# APM32F105xx register map
File version: 1.0
CPU: CM3 r2p1, little endian, no MPU, no FPU, 4 interrupt priority bits
Registers are 32-bit, read-write, reset 0x0 unless marked. A register's access mark holds for its fields unless they carry their own. Offsets are from the block's base; [hi:lo] are bit positions; {n}, {i} and the like mark numbered series.

## TMR6 — Advanced timer
Base 0x40001000
Same registers: TMR7 0x40001400
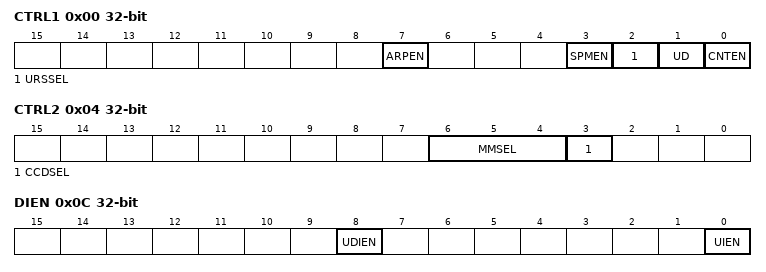
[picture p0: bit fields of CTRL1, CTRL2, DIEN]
0x00 CTRL1 — control register 1
  [7] ARPEN — Auto-reload preload enable
  [3] SPMEN — One-pulse mode
  [2] URSSEL — Update request source
  [1] UD — Update disable
  [0] CNTEN — Counter enable
0x04 CTRL2 — control register 2
  [6:4] MMSEL — Master mode selection
  [3] CCDSEL — Capture/compare DMA selection
0x0C DIEN — DMA/Interrupt enable register
  [8] UDIEN — Update DMA request enable
  [0] UIEN — Update interrupt enable
0x10 STS — status register
  [0] UIFLG — Update interrupt flag
0x14 CEG wo — event generation register
  [0] UEG — Update generation
0x24 CNT — counter
  [15:0] CNT — counter value
0x28 PSC — prescaler
  [15:0] PSC — Prescaler value
0x2C AUTORLD — auto-reload register
  [15:0] AUTORLD — Auto-reload value

## NVIC — Nested Vectored Interrupt Controller
Base 0xE000E000
0x04 ICTR ro — Interrupt Controller Type Register
  [3:0] INTLINESNUM — Total number of interrupt lines in groups
0x100 ISER0 — Interrupt Set-Enable Register
  [31:0] SETENA
0x104 ISER1 — Interrupt Set-Enable Register
  [31:0] SETENA
0x180 ICER0 — Interrupt Clear-Enable Register
  [31:0] CLRENA
0x184 ICER1 — Interrupt Clear-Enable Register
  [31:0] CLRENA
0x200 ISPR0 — Interrupt Set-Pending Register
  [31:0] SETPEND
0x204 ISPR1 — Interrupt Set-Pending Register
  [31:0] SETPEND
0x280 ICPR0 — Interrupt Clear-Pending Register
  [31:0] CLRPEND
0x284 ICPR1 — Interrupt Clear-Pending Register
  [31:0] CLRPEND
0x300 IABR0 ro — Interrupt Active Bit Register
  [31:0] ACTIVE
0x304 IABR1 ro — Interrupt Active Bit Register
  [31:0] ACTIVE
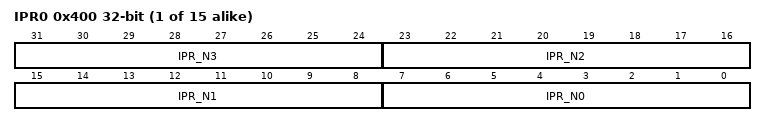
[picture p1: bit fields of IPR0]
{0x400+4i} IPR{i} (i=0..14) — Interrupt Priority Register
  [8n+7:8n] IPR_N{n} (n=0..3)
0xF00 STIR wo — Software Triggered Interrupt Register
  [8:0] INTID — interrupt to be triggered

## DAC — Digital to analog converter
Base 0x40007400
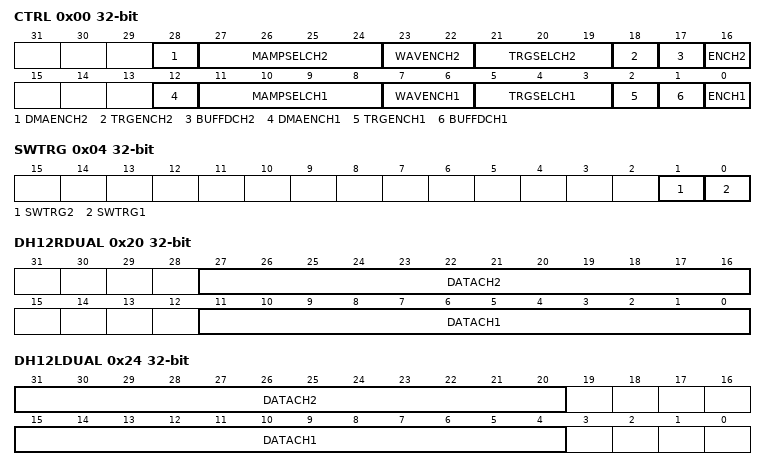
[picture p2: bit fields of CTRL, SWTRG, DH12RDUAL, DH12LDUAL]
0x00 CTRL — Control register (DAC_CTRL)
  [28] DMAENCH2 — DAC channel2 DMA enable
  [27:24] MAMPSELCH2 — DAC channel2 mask/amplitude selector
  [23:22] WAVENCH2 — DAC channel2 noise/triangle wave generation enable
  [21:19] TRGSELCH2 — DAC channel2 trigger selection
  [18] TRGENCH2 — DAC channel2 trigger enable
  [17] BUFFDCH2 — DAC channel2 output buffer disable
  [16] ENCH2 — DAC channel2 enable
  [12] DMAENCH1 — DAC channel1 DMA enable
  [11:8] MAMPSELCH1 — DAC channel1 mask/amplitude selector
  [7:6] WAVENCH1 — DAC channel1 noise/triangle wave generation enable
  [5:3] TRGSELCH1 — DAC channel1 trigger selection
  [2] TRGENCH1 — DAC channel1 trigger enable
  [1] BUFFDCH1 — DAC channel1 output buffer disable
  [0] ENCH1 — DAC channel1 enable
0x04 SWTRG wo — DAC software trigger register (DAC_SWTRG)
  [1] SWTRG2 — DAC channel2 software trigger
  [0] SWTRG1 — DAC channel1 software trigger
0x08 DH12R1 — DAC channel1 12-bit right-aligned data holding register(DAC_DH12R1)
  [11:0] DATA — DAC channel1 12-bit right-aligned data
0x0C DH12L1 — DAC channel1 12-bit left aligned data holding register (DAC_DH12L1)
  [15:4] DATA — DAC channel1 12-bit left-aligned data
0x10 DH8R1 — DAC channel1 8-bit right aligned data holding register (DAC_DH8R1)
  [7:0] DATA — DAC channel1 8-bit right-aligned data
0x14 DH12R2 — DAC channel1 12-bit right-aligned data holding register(DAC_DH12R2)
  [11:0] DATA — DAC channel2 12-bit right-aligned data
0x18 DH12L2 — DAC channel1 12-bit left aligned data holding register (DAC_DH12L2)
  [15:4] DATA — DAC channel2 12-bit left-aligned data
0x1C DH8R2 — DAC channel1 8-bit right aligned data holding register (DAC_DH8R1)
  [7:0] DATA — DAC channel2 8-bit right-aligned data
0x20 DH12RDUAL — Dual DAC 12-bit right-aligned data holding register (DAC_DH12RDUAL), Bits 31:28 Reserved, Bits 15:12 Reserved
  [27:16] DATACH2 — DAC channel2 12-bit right-aligned data
  [11:0] DATACH1 — DAC channel1 12-bit right-aligned data
0x24 DH12LDUAL — DUAL DAC 12-bit left aligned data holding register (DAC_DH12LDUAL), Bits 19:16 Reserved, Bits 3:0 Reserved
  [31:20] DATACH2 — DAC channel2 12-bit right-aligned data
  [15:4] DATACH1 — DAC channel1 12-bit left-aligned data
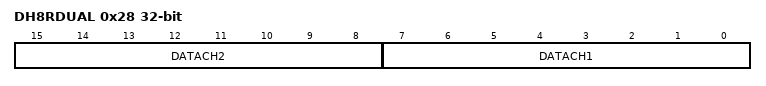
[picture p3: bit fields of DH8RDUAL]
0x28 DH8RDUAL — DUAL DAC 8-bit right aligned data holding register (DAC_DH8RDUAL), Bits 31:16 Reserved
  [15:8] DATACH2 — DAC channel2 8-bit right-aligned data
  [7:0] DATACH1 — DAC channel1 8-bit right-aligned data
0x2C DATAOCH1 ro — DAC channel1 data output register (DAC_DATAOCH1)
  [11:0] DATA — DAC channel1 data output
0x30 DATAOCH2 ro — DAC channel2 data output register (DAC_DATAOCH2)
  [11:0] DATA — DAC channel2 data output
